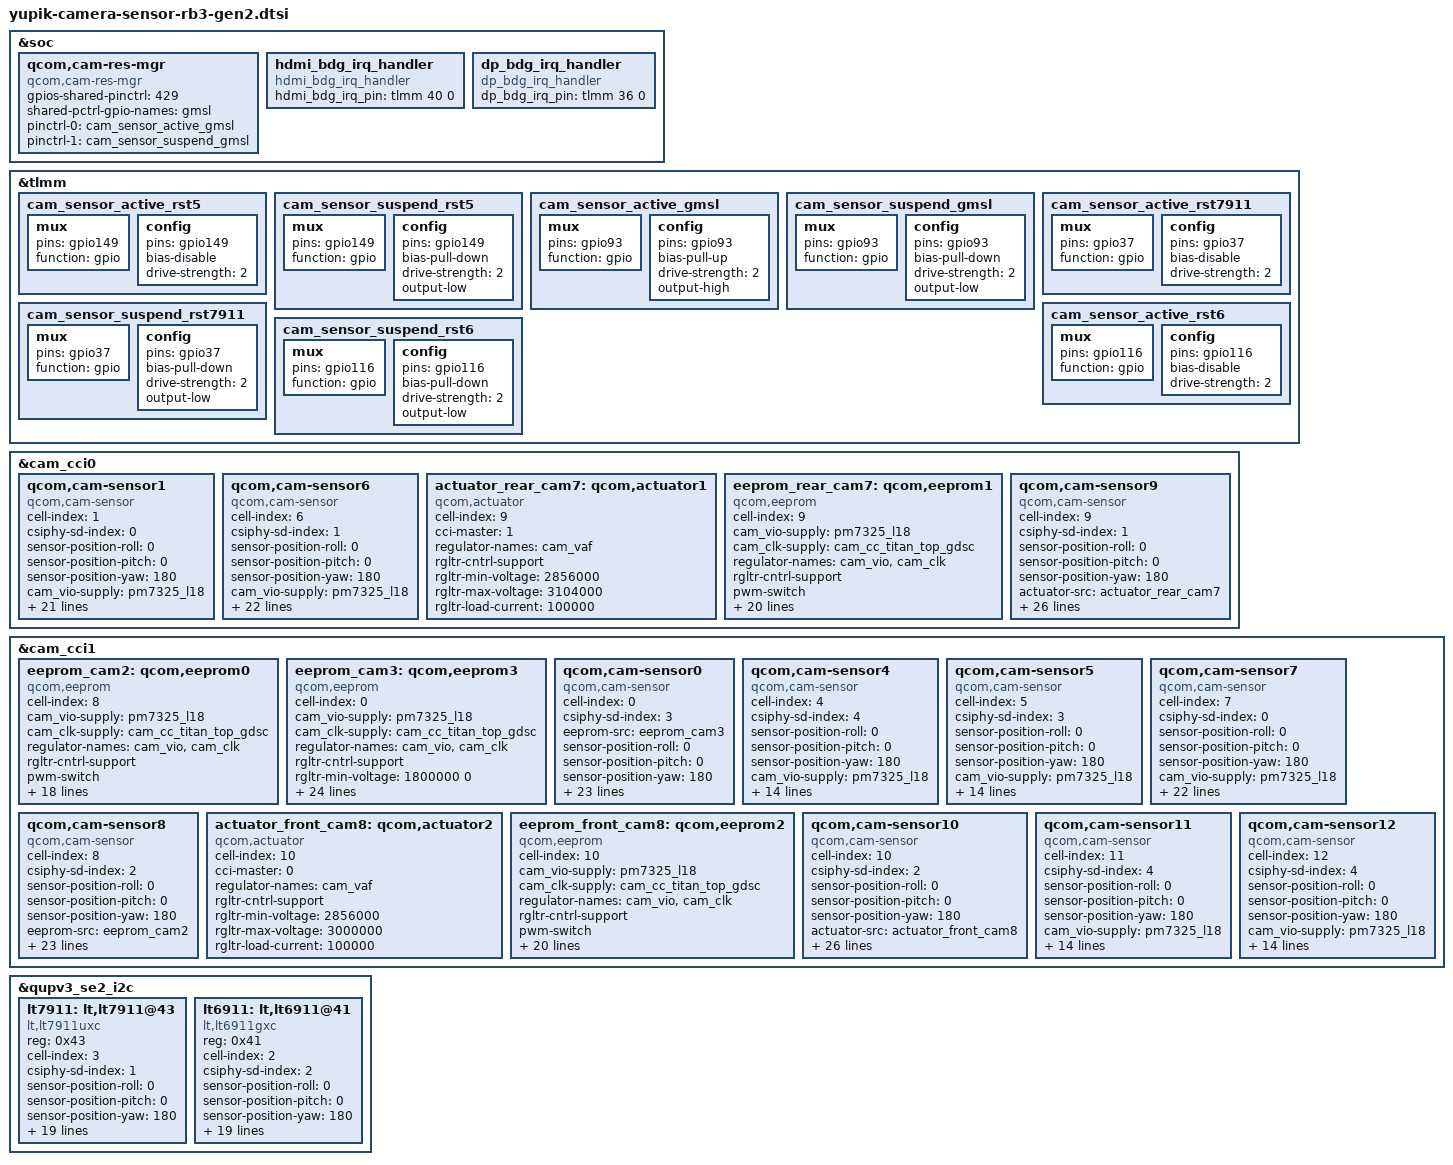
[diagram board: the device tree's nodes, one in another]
// SPDX-License-Identifier: BSD-3-Clause
/*
 * Copyright (c) Qualcomm Technologies, Inc. and/or its subsidiaries.
 */
#include <dt-bindings/msm-camera.h>

&soc {
	qcom,cam-res-mgr {
		compatible = "qcom,cam-res-mgr";
		status = "ok";
		gpios-shared-pinctrl = <429>;
		shared-pctrl-gpio-names = "gmsl";
		pinctrl-names = "gmsl_active", "gmsl_suspend";
		pinctrl-0 = <&cam_sensor_active_gmsl>;
		pinctrl-1 = <&cam_sensor_suspend_gmsl>;
	};
};
&tlmm {
	cam_sensor_active_rst5: cam_sensor_active_rst5 {
		/* RESET 5 */
		mux {
			pins = "gpio149";
			function = "gpio";
		};

		config {
			pins = "gpio149";
			bias-disable; /* No PULL */
			drive-strength = <2>; /* 2 MA */
		};
	};

	cam_sensor_suspend_rst5: cam_sensor_suspend_rst5 {
		/* RESET 5 */
		mux {
			pins = "gpio149";
			function = "gpio";
		};

		config {
			pins = "gpio149";
			bias-pull-down; /* PULL DOWN */
			drive-strength = <2>; /* 2 MA */
			output-low;
		};
	};

	cam_sensor_active_gmsl: cam_sensor_active_gmsl {
		/* GMSL_ENABLE */
		mux {
			pins = "gpio93";
			function = "gpio";
		};

		config {
			pins = "gpio93";
			bias-pull-up;
			drive-strength = <2>; /* 2 MA */
			output-high;
		};
	};

	cam_sensor_suspend_gmsl: cam_sensor_suspend_gmsl {
		/* GMSL_ENABLE */
		mux {
			pins = "gpio93";
			function = "gpio";
		};

		config {
			pins = "gpio93";
			bias-pull-down; /* PULL DOWN */
			drive-strength = <2>; /* 2 MA */
			output-low;
		};
	};

		cam_sensor_active_rst7911: cam_sensor_active_rst7911 {
			/* RESET 7911 */
			mux {
				pins = "gpio37";
				function = "gpio";
			};

			config {
				pins = "gpio37";
				bias-disable; /* No PULL */
				drive-strength = <2>; /* 2 MA */
			};
		};

		cam_sensor_suspend_rst7911: cam_sensor_suspend_rst7911 {
			/* RESET 7911 */
			mux {
				pins = "gpio37";
				function = "gpio";
			};

			config {
				pins = "gpio37";
				bias-pull-down; /* PULL DOWN */
				drive-strength = <2>; /* 2 MA */
				output-low;
			};
		};

		cam_sensor_active_rst6: cam_sensor_active_rst6 {
			/* RESET 6 */
			mux {
				pins = "gpio116";
				function = "gpio";
			};

			config {
				pins = "gpio116";
				bias-disable; /* No PULL */
				drive-strength = <2>; /* 2 MA */
			};
		};

		cam_sensor_suspend_rst6: cam_sensor_suspend_rst6 {
			/* RESET 6 */
			mux {
				pins = "gpio116";
				function = "gpio";
			};

			config {
				pins = "gpio116";
				bias-pull-down; /* PULL DOWN */
				drive-strength = <2>; /* 2 MA */
				output-low;
			};
		};
};

&cam_cci0 {
	/*cam0a-ov9282*/
	qcom,cam-sensor1 {
		cell-index = <1>;
		compatible = "qcom,cam-sensor";
		csiphy-sd-index = <0>;
		sensor-position-roll = <0>;
		sensor-position-pitch = <0>;
		sensor-position-yaw = <180>;
		cam_vio-supply = <&pm7325_l18>;
		cam_clk-supply = <&cam_cc_titan_top_gdsc>;
		regulator-names = "cam_vio", "cam_clk";
		rgltr-cntrl-support;
		pwm-switch;
		rgltr-min-voltage = <1800000 0>;
		rgltr-max-voltage = <1800000 0>;
		rgltr-load-current = <120000 0>;
		gpio-no-mux = <0>;
		pinctrl-names = "cam_default", "cam_suspend";
		pinctrl-0 = <&cam_sensor_mclk0_active
				&cam_sensor_active_rst0>;
		pinctrl-1 = <&cam_sensor_mclk0_suspend
				&cam_sensor_suspend_rst0>;
		gpios = <&tlmm 64 0>,
			<&tlmm 20 0>;
		gpio-reset = <1>;
		gpio-req-tbl-num = <0 1>;
		gpio-req-tbl-flags = <1 0>;
		gpio-req-tbl-label = "CAMIF_MCLK0",
					"CAM_RESET0";
		cci-master = <0>;
		status = "ok";
		clocks = <&camcc CAM_CC_MCLK0_CLK>;
		clock-names = "cam_clk";
		clock-cntl-level = "nominal";
		clock-rates = <24000000>;
	};

    /*cam1-ov9282*/
	qcom,cam-sensor6 {
		cell-index = <6>;
		compatible = "qcom,cam-sensor";
		csiphy-sd-index = <1>;
		sensor-position-roll = <0>;
		sensor-position-pitch = <0>;
		sensor-position-yaw = <180>;
		cam_vio-supply = <&pm7325_l18>;
		cam_clk-supply = <&cam_cc_titan_top_gdsc>;
		regulator-names = "cam_vio", "cam_clk";
		rgltr-cntrl-support;
		pwm-switch;
		rgltr-min-voltage = <1800000 0>;
		rgltr-max-voltage = <1800000 0>;
		rgltr-load-current = <120000 0>;
		gpio-no-mux = <0>;
		pinctrl-names = "cam_default", "cam_suspend";
		pinctrl-0 = <&cam_sensor_mclk1_active
				&cam_sensor_active_rst1>;
		pinctrl-1 = <&cam_sensor_mclk1_suspend
				&cam_sensor_suspend_rst1>;
		gpios = <&tlmm 65 0>,
			<&tlmm 21 0>;
		gpio-reset = <1>;
		gpio-req-tbl-num = <0 1>;
		gpio-req-tbl-flags = <1 0>;
		gpio-req-tbl-label = "CAMIF_MCLK1",
					"CAM_RESET1";
		sensor-mode = <0>;
		cci-master = <1>;
		status = "ok";
		clocks = <&camcc CAM_CC_MCLK1_CLK>;
		clock-names = "cam_clk";
		clock-cntl-level = "nominal";
		clock-rates = <24000000>;
	};

	//cam1 interpose on dk csi0
	actuator_rear_cam7: qcom,actuator1 {
		cell-index = <9>;
		compatible = "qcom,actuator";
		cci-master = <1>;
		regulator-names = "cam_vaf";
		rgltr-cntrl-support;
		rgltr-min-voltage = <2856000>;
		rgltr-max-voltage = <3104000>;
		rgltr-load-current = <100000>;
	};

	eeprom_rear_cam7: qcom,eeprom1 {
		cell-index = <9>;
		compatible = "qcom,eeprom";
		cam_vio-supply = <&pm7325_l18>;
		cam_clk-supply = <&cam_cc_titan_top_gdsc>;
		regulator-names = "cam_vio", "cam_clk";
		rgltr-cntrl-support;
		pwm-switch;
		rgltr-min-voltage = <1800000 0>;
		rgltr-max-voltage = <1800000 0>;
		rgltr-load-current = <120000 0>;
		gpio-no-mux = <0>;
		pinctrl-names = "cam_default", "cam_suspend";
		pinctrl-0 = <&cam_sensor_mclk1_active
				 &cam_sensor_active_rst1>;
		pinctrl-1 = <&cam_sensor_mclk1_suspend
				 &cam_sensor_suspend_rst1>;
		gpios = <&tlmm 65 0>,
			<&tlmm 21 0>,
			<&pm7250b_gpios 3 0>;
		gpio-reset = <1>;
		gpio-custom1 = <2>;
		gpio-req-tbl-num = <0 1 2>;
		gpio-req-tbl-flags = <1 0 0>;
		gpio-req-tbl-label = "CAMIF_MCLK1",
					"CAM_RESET1",
					"CAM_CUSTOM1";
		sensor-mode = <0>;
		cci-master = <1>;
		status = "ok";
		clocks = <&camcc CAM_CC_MCLK1_CLK>;
		clock-names = "cam_clk";
		clock-cntl-level = "nominal";
		clock-rates = <24000000>;
	};

	/*cam1-imx586/imx686*/
	qcom,cam-sensor9 {
		cell-index = <9>;
		compatible = "qcom,cam-sensor";
		csiphy-sd-index = <1>;
		sensor-position-roll = <0>;
		sensor-position-pitch = <0>;
		sensor-position-yaw = <180>;
		actuator-src = <&actuator_rear_cam7>;
		eeprom-src = <&eeprom_rear_cam7>;
		cam_vio-supply = <&pm7325_l18>;
		cam_clk-supply = <&cam_cc_titan_top_gdsc>;
		regulator-names = "cam_vio", "cam_clk";
		rgltr-cntrl-support;
		pwm-switch;
		rgltr-min-voltage = <1800000 0>;
		rgltr-max-voltage = <1800000 0>;
		rgltr-load-current = <120000 0>;
		gpio-no-mux = <0>;
		pinctrl-names = "cam_default", "cam_suspend";
		pinctrl-0 = <&cam_sensor_mclk1_active
				&cam_sensor_active_rst1>;
		pinctrl-1 = <&cam_sensor_mclk1_suspend
				&cam_sensor_suspend_rst1>;
		gpios = <&tlmm 65 0>,
			<&tlmm 21 0>,
			<&pm7250b_gpios 3 0>;
		gpio-reset = <1>;
		gpio-custom1 = <2>;
		gpio-req-tbl-num = <0 1 2>;
		gpio-req-tbl-flags = <1 0 0>;
		gpio-req-tbl-label = "CAMIF_MCLK1",
					"CAM_RESET1",
					"CAM_CUSTOM1";
		sensor-mode = <0>;
		cci-master = <1>;
		status = "ok";
		clocks = <&camcc CAM_CC_MCLK1_CLK>;
		clock-names = "cam_clk";
		clock-cntl-level = "nominal";
		clock-rates = <24000000>;
	};
};

&cam_cci1 {
	eeprom_cam2: qcom,eeprom0 {
		cell-index = <8>;
		compatible = "qcom,eeprom";
		cam_vio-supply = <&pm7325_l18>;
		cam_clk-supply = <&cam_cc_titan_top_gdsc>;
		regulator-names = "cam_vio", "cam_clk";
		rgltr-cntrl-support;
		pwm-switch;
		rgltr-min-voltage = <1800000 0>;
		rgltr-max-voltage = <1800000 0>;
		rgltr-load-current = <120000 0>;
		gpio-no-mux = <0>;
		pinctrl-names = "cam_default", "cam_suspend";
		pinctrl-0 = <&cam_sensor_mclk2_active
				 &cam_sensor_active_rst2>;
		pinctrl-1 = <&cam_sensor_mclk2_suspend
				 &cam_sensor_suspend_rst2>;
		gpios = <&tlmm 66 0>,
			<&tlmm 77 0>;
		gpio-reset = <1>;
		gpio-req-tbl-num = <0 1>;
		gpio-req-tbl-flags = <1 0>;
		gpio-req-tbl-label = "CAMIF_MCLK2",
					"CAM_RESET2";
		sensor-mode = <0>;
		cci-master = <0>;
		status = "ok";
		clocks = <&camcc CAM_CC_MCLK2_CLK>;
		clock-names = "cam_clk";
		clock-cntl-level = "nominal";
		clock-rates = <24000000>;
	};

	eeprom_cam3: qcom,eeprom3 {
		cell-index = <0>;
		compatible = "qcom,eeprom";
		cam_vio-supply = <&pm7325_l18>;
		cam_clk-supply = <&cam_cc_titan_top_gdsc>;
		regulator-names = "cam_vio","cam_clk";
		rgltr-cntrl-support;
		rgltr-min-voltage = <1800000 0>;
		rgltr-max-voltage = <1800000 0>;
		rgltr-load-current = <120000 0>;
		gpio-no-mux = <0>;
		pinctrl-names = "cam_default", "cam_suspend";
		pinctrl-0 = <&cam_sensor_mclk3_active
			&cam_sensor_active_rst3>;
		pinctrl-1 = <&cam_sensor_mclk3_suspend
			&cam_sensor_suspend_rst3>;
		gpios = <&tlmm 67 0>,
			<&tlmm 78 0>;
		gpio-reset = <1>;
		gpio-req-tbl-num = <0 1>;
		gpio-req-tbl-flags = <1 0>;
		gpio-req-tbl-label = "CAMIF_MCLK3",
			"CAM_RESET3";
		sensor-position = <1>;
		sensor-mode = <0>;
		cci-master = <1>;
		qcom,cam-power-seq-type ="cam_reset","cam_vio","cam_clk","cam_reset";
		qcom,cam-power-seq-val = "cam_reset","cam_vio"
			,"cam_mclk","cam_reset";
		qcom,cam-power-seq-cfg-val = <0 1 24000000 1>;
		qcom,cam-power-seq-delay = <1 0 1 18>;
		status = "ok";
		clocks = <&camcc CAM_CC_MCLK3_CLK>;
		clock-names = "cam_clk";
		clock-cntl-level = "nominal";
		clock-rates = <24000000>;
	};

	/*cam3-imx577*/
	qcom,cam-sensor0 {
		cell-index = <0>;
		compatible = "qcom,cam-sensor";
		csiphy-sd-index = <3>;
		eeprom-src = <&eeprom_cam3>;
		sensor-position-roll = <0>;
		sensor-position-pitch = <0>;
		sensor-position-yaw = <180>;
		cam_vio-supply = <&pm7325_l18>;
		cam_clk-supply = <&cam_cc_titan_top_gdsc>;
		regulator-names = "cam_vio", "cam_clk";
		rgltr-cntrl-support;
		pwm-switch;
		rgltr-min-voltage = <1800000 0>;
		rgltr-max-voltage = <1800000 0>;
		rgltr-load-current = <120000 0>;
		gpio-no-mux = <0>;
		pinctrl-names = "cam_default", "cam_suspend";
		pinctrl-0 = <&cam_sensor_mclk3_active
				&cam_sensor_active_rst3>;
		pinctrl-1 = <&cam_sensor_mclk3_suspend
				&cam_sensor_suspend_rst3>;
		gpios = <&tlmm 67 0>,
			<&tlmm 78 0>;
		gpio-reset = <1>;
		gpio-req-tbl-num = <0 1>;
		gpio-req-tbl-flags = <1 0>;
		gpio-req-tbl-label = "CAMIF_MCLK3",
					"CAM_RESET3";
		sensor-mode = <0>;
		cci-master = <1>;
		status = "ok";
		clocks = <&camcc CAM_CC_MCLK3_CLK>;
		clock-names = "cam_clk";
		clock-cntl-level = "nominal";
		clock-rates = <24000000>;
	};

	/*gmsl1-GMSL*/
	qcom,cam-sensor4 {
		cell-index = <4>;
		compatible = "qcom,cam-sensor";
		csiphy-sd-index = <4>;
		sensor-position-roll = <0>;
		sensor-position-pitch = <0>;
		sensor-position-yaw = <180>;
		cam_vio-supply = <&pm7325_l18>;
		regulator-names = "cam_vio";
		rgltr-cntrl-support;
		pwm-switch;
		rgltr-min-voltage = <1800000>;
		rgltr-max-voltage = <1800000>;
		rgltr-load-current = <120000>;
		gpio-no-mux = <0>;
		gpios = <&tlmm 93 0>;
		gpio-reset = <0>;
		gpio-req-tbl-num = <0>;
		gpio-req-tbl-flags = <0>;
		gpio-req-tbl-label = "CAM_4";
		sensor-mode = <0>;
		cci-master = <1>;
		status = "ok";
	};

	/*gmsl2-GMSL*/
	qcom,cam-sensor5 {
		cell-index = <5>;
		compatible = "qcom,cam-sensor";
		csiphy-sd-index = <3>;
		sensor-position-roll = <0>;
		sensor-position-pitch = <0>;
		sensor-position-yaw = <180>;
		cam_vio-supply = <&pm7325_l18>;
		regulator-names = "cam_vio";
		rgltr-cntrl-support;
		pwm-switch;
		rgltr-min-voltage = <1800000>;
		rgltr-max-voltage = <1800000>;
		rgltr-load-current = <120000>;
		gpio-no-mux = <0>;
		gpios = <&tlmm 93 0>;
		gpio-reset = <0>;
		gpio-req-tbl-num = <0>;
		gpio-req-tbl-flags = <0>;
		gpio-req-tbl-label = "CAM_5";
		sensor-mode = <0>;
		cci-master = <1>;
		status = "ok";
	};

	/*cam0b-ov9282*/
	qcom,cam-sensor7 {
		cell-index = <7>;
		compatible = "qcom,cam-sensor";
		csiphy-sd-index = <0>;
		sensor-position-roll = <0>;
		sensor-position-pitch = <0>;
		sensor-position-yaw = <180>;
		cam_vio-supply = <&pm7325_l18>;
		cam_clk-supply = <&cam_cc_titan_top_gdsc>;
		regulator-names = "cam_vio", "cam_clk";
		rgltr-cntrl-support;
		pwm-switch;
		rgltr-min-voltage = <1800000 0>;
		rgltr-max-voltage = <1800000 0>;
		rgltr-load-current = <120000 0>;
		gpio-no-mux = <0>;
		pinctrl-names = "cam_default", "cam_suspend";
		pinctrl-0 = <&cam_sensor_mclk4_active
			&cam_sensor_active_rst5>;
		pinctrl-1 = <&cam_sensor_mclk4_suspend
			&cam_sensor_suspend_rst5>;
		gpios = <&tlmm 68 0>,
			<&tlmm 149 0>;
		gpio-reset = <1>;
		gpio-req-tbl-num = <0 1>;
		gpio-req-tbl-flags = <1 0>;
		gpio-req-tbl-label = "CAMIF_MCLK4",
				"CAM_RESET5";
		sensor-mode = <0>;
		cci-master = <0>;
		status = "ok";
		clocks = <&camcc CAM_CC_MCLK4_CLK>;
		clock-names = "cam_clk";
		clock-cntl-level = "nominal";
		clock-rates = <24000000>;
	};

	/*cam2-imx577*/
	qcom,cam-sensor8 {
		cell-index = <8>;
		compatible = "qcom,cam-sensor";
		csiphy-sd-index = <2>;
		sensor-position-roll = <0>;
		sensor-position-pitch = <0>;
		sensor-position-yaw = <180>;
		eeprom-src = <&eeprom_cam2>;
		cam_vio-supply = <&pm7325_l18>;
		cam_clk-supply = <&cam_cc_titan_top_gdsc>;
		regulator-names = "cam_vio", "cam_clk";
		rgltr-cntrl-support;
		pwm-switch;
		rgltr-min-voltage = <1800000 0>;
		rgltr-max-voltage = <1800000 0>;
		rgltr-load-current = <120000 0>;
		gpio-no-mux = <0>;
		pinctrl-names = "cam_default", "cam_suspend";
		pinctrl-0 = <&cam_sensor_mclk2_active
				 &cam_sensor_active_rst2>;
		pinctrl-1 = <&cam_sensor_mclk2_suspend
				 &cam_sensor_suspend_rst2>;
		gpios = <&tlmm 66 0>,
			<&tlmm 77 0>;
		gpio-reset = <1>;
		gpio-req-tbl-num = <0 1>;
		gpio-req-tbl-flags = <1 0>;
		gpio-req-tbl-label = "CAMIF_MCLK2",
					"CAM_RESET2";
		sensor-mode = <0>;
		cci-master = <0>;
		status = "ok";
		clocks = <&camcc CAM_CC_MCLK2_CLK>;
		clock-names = "cam_clk";
		clock-cntl-level = "nominal";
		clock-rates = <24000000>;
	};

	actuator_front_cam8: qcom,actuator2 {
		cell-index = <10>;
		compatible = "qcom,actuator";
		cci-master = <0>;
		regulator-names = "cam_vaf";
		rgltr-cntrl-support;
		rgltr-min-voltage = <2856000>;
		rgltr-max-voltage = <3000000>;
		rgltr-load-current = <100000>;
	};

	eeprom_front_cam8: qcom,eeprom2 {
		cell-index = <10>;
		compatible = "qcom,eeprom";
		cam_vio-supply = <&pm7325_l18>;
		cam_clk-supply = <&cam_cc_titan_top_gdsc>;
		regulator-names = "cam_vio", "cam_clk";
		rgltr-cntrl-support;
		pwm-switch;
		rgltr-min-voltage = <1800000 0>;
		rgltr-max-voltage = <1800000 0>;
		rgltr-load-current = <120000 0>;
		gpio-no-mux = <0>;
		pinctrl-names = "cam_default", "cam_suspend";
		pinctrl-0 = <&cam_sensor_mclk2_active
				 &cam_sensor_active_rst2>;
		pinctrl-1 = <&cam_sensor_mclk2_suspend
				 &cam_sensor_suspend_rst2>;
		gpios = <&tlmm 66 0>,
			<&tlmm 77 0>,
			<&pm7250b_gpios 7 0>;
		gpio-reset = <1>;
		gpio-custom1 = <2>;
		gpio-req-tbl-num = <0 1 2>;
		gpio-req-tbl-flags = <1 0 0>;
		gpio-req-tbl-label = "CAMIF_MCLK2",
					"CAM_RESET2",
					"CAM_CUSTOM1";
		sensor-mode = <0>;
		cci-master = <0>;
		status = "ok";
		clocks = <&camcc CAM_CC_MCLK2_CLK>;
		clock-names = "cam_clk";
		clock-cntl-level = "nominal";
		clock-rates = <24000000>;
	};

	/*cam2-imx586/imx686*/
	qcom,cam-sensor10 {
		cell-index = <10>;
		compatible = "qcom,cam-sensor";
		csiphy-sd-index = <2>;
		sensor-position-roll = <0>;
		sensor-position-pitch = <0>;
		sensor-position-yaw = <180>;
		actuator-src = <&actuator_front_cam8>;
		eeprom-src = <&eeprom_front_cam8>;
		cam_vio-supply = <&pm7325_l18>;
		cam_clk-supply = <&cam_cc_titan_top_gdsc>;
		regulator-names = "cam_vio", "cam_clk";
		rgltr-cntrl-support;
		pwm-switch;
		rgltr-min-voltage = <1800000 0>;
		rgltr-max-voltage = <1800000 0>;
		rgltr-load-current = <120000 0>;
		gpio-no-mux = <0>;
		pinctrl-names = "cam_default", "cam_suspend";
		pinctrl-0 = <&cam_sensor_mclk2_active
				 &cam_sensor_active_rst2>;
		pinctrl-1 = <&cam_sensor_mclk2_suspend
				 &cam_sensor_suspend_rst2>;
		gpios = <&tlmm 66 0>,
			<&tlmm 77 0>,
			<&pm7250b_gpios 7 0>;
		gpio-reset = <1>;
		gpio-custom1 = <2>;
		gpio-req-tbl-num = <0 1 2>;
		gpio-req-tbl-flags = <1 0 0>;
		gpio-req-tbl-label = "CAMIF_MCLK2",
					"CAM_RESET2",
					"CAM_CUSTOM1";
		sensor-mode = <0>;
		cci-master = <0>;
		status = "ok";
		clocks = <&camcc CAM_CC_MCLK2_CLK>;
		clock-names = "cam_clk";
		clock-cntl-level = "nominal";
		clock-rates = <24000000>;
	};

	/* GMSL 3 */
	qcom,cam-sensor11 {
		cell-index = <11>;
		compatible = "qcom,cam-sensor";
		csiphy-sd-index = <4>;
		sensor-position-roll = <0>;
		sensor-position-pitch = <0>;
		sensor-position-yaw = <180>;
		cam_vio-supply = <&pm7325_l18>;
		regulator-names = "cam_vio";
		rgltr-cntrl-support;
		pwm-switch;
		rgltr-min-voltage = <1800000>;
		rgltr-max-voltage = <1800000>;
		rgltr-load-current = <120000>;
		gpio-no-mux = <0>;
		gpios = <&tlmm 93 0>;
		gpio-reset = <0>;
		gpio-req-tbl-num = <0>;
		gpio-req-tbl-flags = <0>;
		gpio-req-tbl-label = "CAM_9";
		sensor-mode = <0>;
		cci-master = <1>;
		status = "ok";
	};

	/* GMSL 4 */
	qcom,cam-sensor12 {
		cell-index = <12>;
		compatible = "qcom,cam-sensor";
		csiphy-sd-index = <4>;
		sensor-position-roll = <0>;
		sensor-position-pitch = <0>;
		sensor-position-yaw = <180>;
		cam_vio-supply = <&pm7325_l18>;
		regulator-names = "cam_vio";
		rgltr-cntrl-support;
		pwm-switch;
		rgltr-min-voltage = <1800000>;
		rgltr-max-voltage = <1800000>;
		rgltr-load-current = <120000>;
		gpio-no-mux = <0>;
		gpios = <&tlmm 93 0>;
		gpio-reset = <0>;
		gpio-req-tbl-num = <0>;
		gpio-req-tbl-flags = <0>;
		gpio-req-tbl-label = "CAM_10";
		sensor-mode = <0>;
		cci-master = <1>;
		status = "ok";
	};
};

/*lt7911uxc-dp*/
&qupv3_se2_i2c {
	status = "ok";
	lt7911: lt,lt7911@43 {
		compatible = "lt,lt7911uxc";
		reg = <0x43>;
		cell-index = <3>;
		csiphy-sd-index = <1>;
		sensor-position-roll = <0>;
		sensor-position-pitch = <0>;
		sensor-position-yaw = <180>;
		cam_clk-supply = <&cam_cc_titan_top_gdsc>;
		regulator-names = "cam_clk";
		rgltr-cntrl-support;
		pwm-switch;
		rgltr-min-voltage = <0>;
		rgltr-max-voltage = <0>;
		rgltr-load-current = <0>;
		gpio-no-mux = <0>;
		pinctrl-names = "cam_default", "cam_suspend";
		pinctrl-0 = <&cam_sensor_active_rst7911>;
		pinctrl-1 = <&cam_sensor_suspend_rst7911>;
		gpios = <&tlmm 37 0>;
		gpio-reset = <0>;
		gpio-req-tbl-num = <0>;
		gpio-req-tbl-flags = <0>;
		gpio-req-tbl-label = "CAM_RESET3";
		sensor-mode = <0>;
		clocks = <&camcc CAM_CC_MCLK3_CLK>;
		clock-names = "cam_clk";
		clock-cntl-level = "turbo";
		clock-rates = <24000000>;
    };
};

/*lt6911gxc-hdmi*/
&qupv3_se2_i2c {
	status = "ok";
	lt6911: lt,lt6911@41 {
		compatible = "lt,lt6911gxc";
		reg = <0x41>;
		cell-index = <2>;
		csiphy-sd-index = <2>;
		sensor-position-roll = <0>;
		sensor-position-pitch = <0>;
		sensor-position-yaw = <180>;
		cam_clk-supply = <&cam_cc_titan_top_gdsc>;
		regulator-names = "cam_clk";
		rgltr-cntrl-support;
		pwm-switch;
		rgltr-min-voltage = <0>;
		rgltr-max-voltage = <0>;
		rgltr-load-current = <0>;
		gpio-no-mux = <0>;
		pinctrl-names = "cam_default", "cam_suspend";
		pinctrl-0 = <&cam_sensor_active_rst6>;
		pinctrl-1 = <&cam_sensor_suspend_rst6>;
		gpios = <&tlmm 116 0>;
		gpio-reset = <0>;
		gpio-req-tbl-num = <0>;
		gpio-req-tbl-flags = <0>;
		gpio-req-tbl-label = "CAM_RESET6";
		sensor-mode = <0>;
		clocks = <&camcc CAM_CC_MCLK3_CLK>;
		clock-names = "cam_clk";
		clock-cntl-level = "turbo";
		clock-rates = <24000000>;
	};
};

&soc {
	hdmi_bdg_irq_handler: hdmi_bdg_irq_handler {
		compatible = "hdmi_bdg_irq_handler";
		hdmi_bdg_irq_pin = <&tlmm 40 0>;
	};

	dp_bdg_irq_handler: dp_bdg_irq_handler {
		compatible = "dp_bdg_irq_handler";
		dp_bdg_irq_pin = <&tlmm 36 0>;
	};
};
